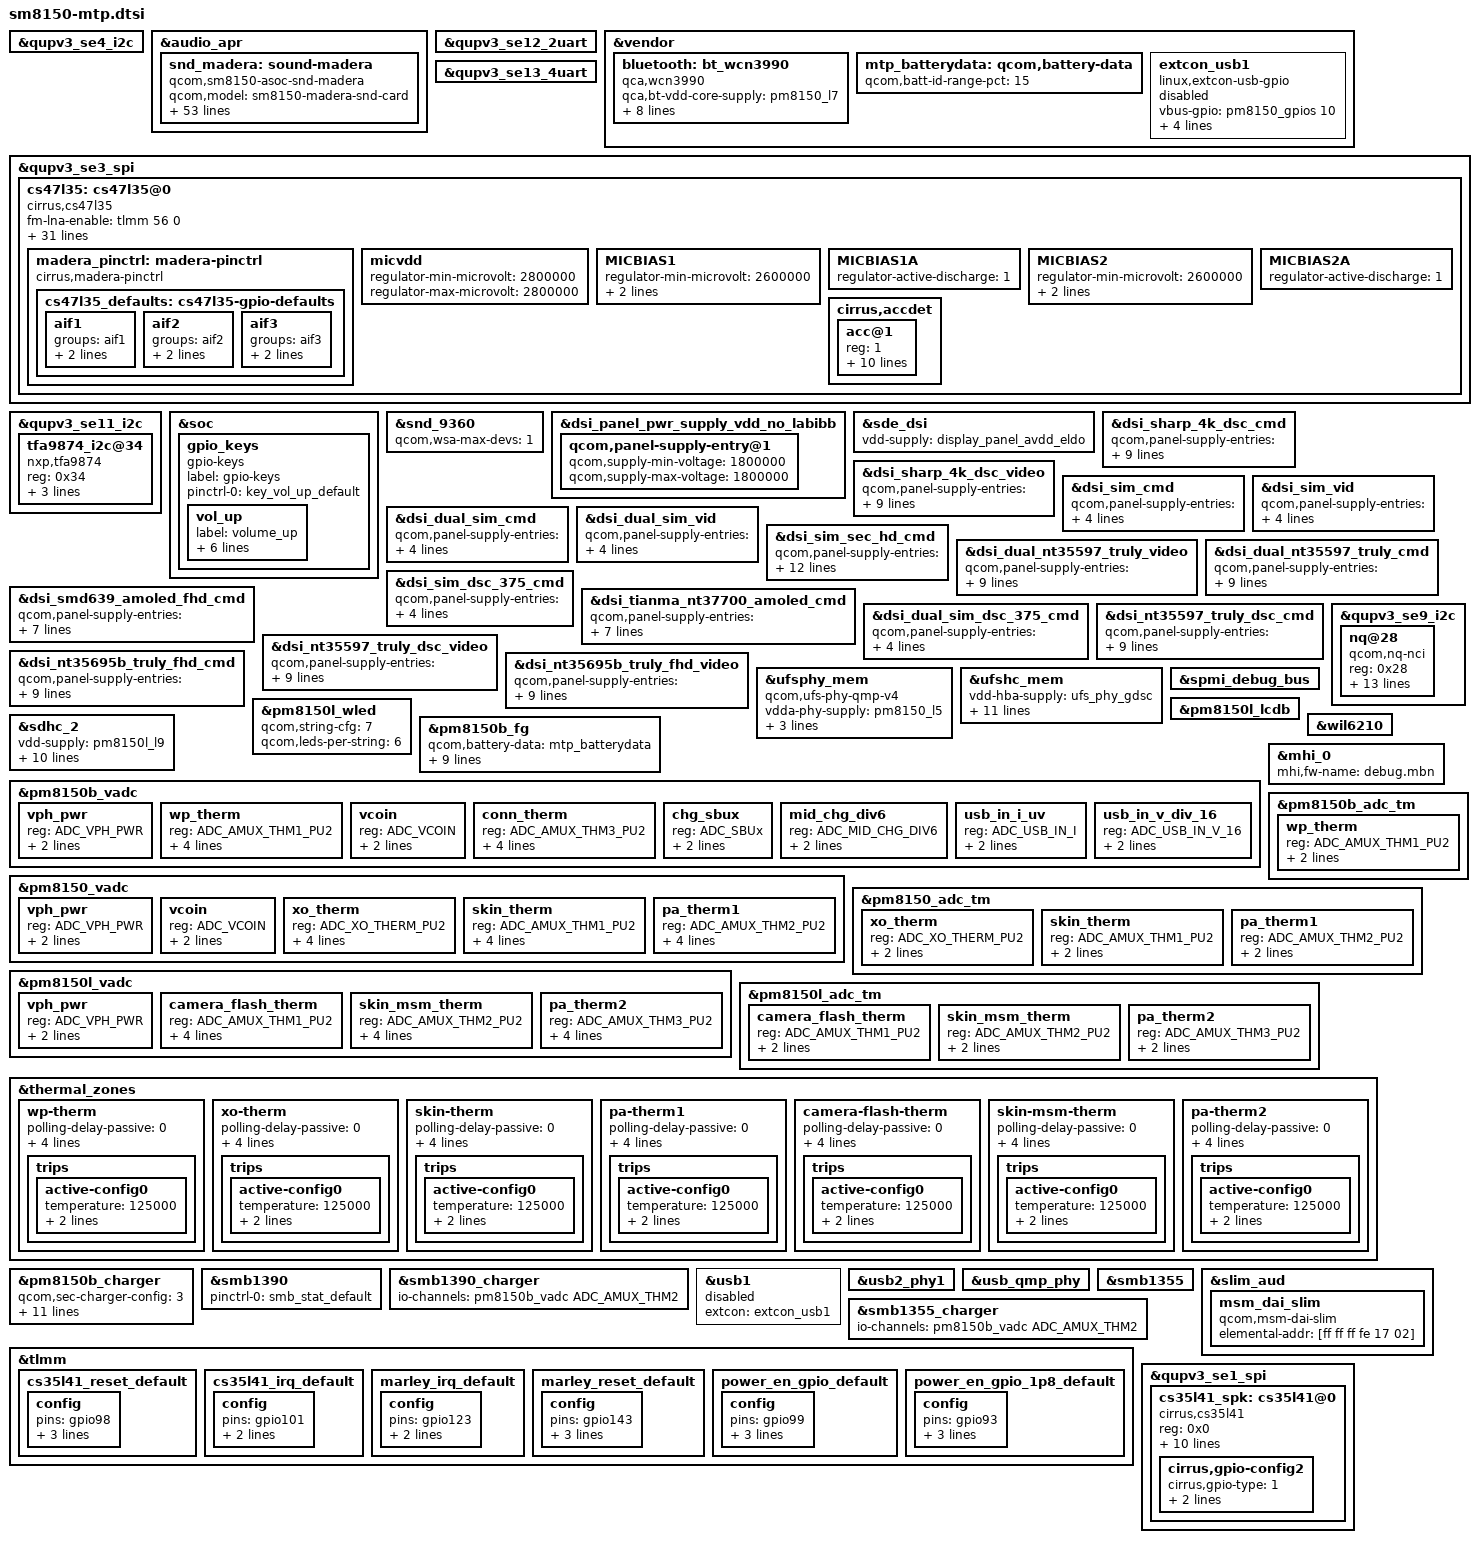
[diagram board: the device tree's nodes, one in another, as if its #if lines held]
/* Copyright (c) 2017-2018, The Linux Foundation. All rights reserved.
 *
 * This program is free software; you can redistribute it and/or modify
 * it under the terms of the GNU General Public License version 2 and
 * only version 2 as published by the Free Software Foundation.
 *
 * This program is distributed in the hope that it will be useful,
 * but WITHOUT ANY WARRANTY; without even the implied warranty of
 * MERCHANTABILITY or FITNESS FOR A PARTICULAR PURPOSE.  See the
 * GNU General Public License for more details.
 */

#include <dt-bindings/gpio/gpio.h>
#include <dt-bindings/input/input.h>
#include <generated/autoconf.h>

#include "sm8150-pmic-overlay.dtsi"
#include "sm8150-sde-display.dtsi"
#ifdef CONFIG_PRODUCT_HEART
#include "sm8150-camera-sensor-heart.dtsi"
#elif defined(CONFIG_PRODUCT_ZIPPO)
#include "sm8150-camera-sensor-zippo.dtsi"
#else
#include "sm8150-camera-sensor-mtp.dtsi"
#endif
#include "sm8150-thermal-overlay.dtsi"

&qupv3_se4_i2c {
#include "smb1390.dtsi"
#include "smb1355.dtsi"
};
#ifdef CONFIG_PRODUCT_HEART
&audio_apr {
	snd_madera: sound-madera {
		compatible = "qcom,sm8150-asoc-snd-madera";
		qcom,model = "sm8150-madera-snd-card";

		asoc-platform = <&pcm0>, <&pcm1>, <&pcm2>, <&voip>, <&voice>,
				<&loopback>, <&compress>, <&hostless>,
				<&afe>, <&lsm>, <&routing>, <&compr>,
				<&pcm_noirq>, <&cs47l35>;
		asoc-platform-names = "msm-pcm-dsp.0", "msm-pcm-dsp.1",
				"msm-pcm-dsp.2", "msm-voip-dsp",
				"msm-pcm-voice", "msm-pcm-loopback",
				"msm-compress-dsp", "msm-pcm-hostless",
				"msm-pcm-afe", "msm-lsm-client",
				"msm-pcm-routing", "msm-compr-dsp",
				"msm-pcm-dsp-noirq","cs47l35-codec";
		asoc-cpu = <&dai_hdmi>, <&dai_dp>,
				<&dai_mi2s0>, <&dai_mi2s1>,
				<&dai_mi2s2>, <&dai_mi2s3>,
				<&dai_mi2s4>, <&dai_pri_auxpcm>,
				<&dai_sec_auxpcm>, <&dai_tert_auxpcm>,
				<&dai_quat_auxpcm>, <&dai_quin_auxpcm>,
				<&sb_0_rx>, <&sb_0_tx>, <&sb_1_rx>, <&sb_1_tx>,
				<&sb_2_rx>, <&sb_2_tx>, <&sb_3_rx>, <&sb_3_tx>,
				<&sb_4_rx>, <&sb_4_tx>, <&sb_5_tx>,
				<&afe_pcm_rx>, <&afe_pcm_tx>, <&afe_proxy_rx>,
				<&afe_proxy_tx>, <&incall_record_rx>,
				<&incall_record_tx>, <&incall_music_rx>,
				<&incall_music_2_rx>, <&sb_5_rx>, <&sb_6_rx>,
				<&sb_7_rx>, <&sb_7_tx>, <&sb_8_tx>,
				<&usb_audio_rx>, <&usb_audio_tx>,
				<&dai_pri_tdm_rx_0>, <&dai_pri_tdm_tx_0>,
				<&dai_sec_tdm_rx_0>, <&dai_sec_tdm_tx_0>,
				<&dai_tert_tdm_rx_0>, <&dai_tert_tdm_tx_0>,
				<&dai_quat_tdm_rx_0>, <&dai_quat_tdm_tx_0>,
				<&dai_quin_tdm_rx_0>, <&dai_quin_tdm_tx_0>;
		asoc-cpu-names = "msm-dai-q6-hdmi.8",  "msm-dai-q6-dp.24608",
				"msm-dai-q6-mi2s.0", "msm-dai-q6-mi2s.1",
				"msm-dai-q6-mi2s.2", "msm-dai-q6-mi2s.3",
				"msm-dai-q6-mi2s.4", "msm-dai-q6-auxpcm.1",
				"msm-dai-q6-auxpcm.2", "msm-dai-q6-auxpcm.3",
				"msm-dai-q6-auxpcm.4", "msm-dai-q6-auxpcm.5",
				"msm-dai-q6-dev.16384", "msm-dai-q6-dev.16385",
				"msm-dai-q6-dev.16386", "msm-dai-q6-dev.16387",
				"msm-dai-q6-dev.16388", "msm-dai-q6-dev.16389",
				"msm-dai-q6-dev.16390", "msm-dai-q6-dev.16391",
				"msm-dai-q6-dev.16392", "msm-dai-q6-dev.16393",
				"msm-dai-q6-dev.16395", "msm-dai-q6-dev.224",
				"msm-dai-q6-dev.225", "msm-dai-q6-dev.241",
				"msm-dai-q6-dev.240", "msm-dai-q6-dev.32771",
				"msm-dai-q6-dev.32772", "msm-dai-q6-dev.32773",
				"msm-dai-q6-dev.32770", "msm-dai-q6-dev.16394",
				"msm-dai-q6-dev.16396", "msm-dai-q6-dev.16398",
				"msm-dai-q6-dev.16399", "msm-dai-q6-dev.16401",
				"msm-dai-q6-dev.28672", "msm-dai-q6-dev.28673",
				"msm-dai-q6-tdm.36864", "msm-dai-q6-tdm.36865",
				"msm-dai-q6-tdm.36880", "msm-dai-q6-tdm.36881",
				"msm-dai-q6-tdm.36896", "msm-dai-q6-tdm.36897",
				"msm-dai-q6-tdm.36912", "msm-dai-q6-tdm.36913",
				"msm-dai-q6-tdm.36928", "msm-dai-q6-tdm.36929";
		fsa4480-i2c-handle = <&fsa4480>;
	};
};
#endif
&qupv3_se12_2uart {
	status = "ok";
};

&vendor {
	bluetooth: bt_wcn3990 {
		compatible = "qca,wcn3990";
		qca,bt-vdd-core-supply = <&pm8150_l7>;
		qca,bt-vdd-pa-supply = <&pm8150l_l2>;
		qca,bt-vdd-ldo-supply = <&pm8150l_l11>;

		qca,bt-vdd-core-voltage-level = <1800000 1800000>;
		qca,bt-vdd-pa-voltage-level = <1304000 1304000>;
		qca,bt-vdd-ldo-voltage-level = <3312000 3312000>;

		qca,bt-vdd-core-current-level = <0>; /* LPM/PFM */
		qca,bt-vdd-pa-current-level = <0>; /* LPM/PFM */
		qca,bt-vdd-ldo-current-level = <0>; /* LPM/PFM */
	};

	mtp_batterydata: qcom,battery-data {
		qcom,batt-id-range-pct = <15>;
		#include "Lenovo_heart_batterydate_Aug28th2018_scud_3300mAh_averaged_MasterSlave.dtsi"
		#include "Lenovo_Zippo_ATL_4000mAh_averaged_MasterSlave_Jan4rd2019_PM8150BGUI10013.dtsi"
	};

	extcon_usb1: extcon_usb1 {
#if defined(CONFIG_PRODUCT_HEART)||defined(CONFIG_PRODUCT_ZIPPO)
		status = "disabled";
#endif
		compatible = "linux,extcon-usb-gpio";
		vbus-gpio = <&pm8150_gpios 10 GPIO_ACTIVE_HIGH>;
		id-gpio = <&tlmm 101 GPIO_ACTIVE_HIGH>;
		vbus-out-gpio = <&pm8150_gpios 9 GPIO_ACTIVE_HIGH>;

		pinctrl-names = "default";
		pinctrl-0 = <&usb2_vbus_det_default
			     &usb2_id_det_default
			     &usb2_vbus_boost_default>;
	};
};

&qupv3_se13_4uart {
	status = "ok";
};

&qupv3_se3_spi {
	status = "ok";
};

&qupv3_se4_i2c {
	status = "ok";
};

#ifdef CONFIG_PRODUCT_ZIPPO
&qupv3_se11_i2c {
	status = "ok";
	tfa9874_i2c@34 {
		compatible = "nxp,tfa9874";
		reg = <0x34>;
		status = "ok";
		reset-gpio = <&tlmm 98 0x0>;
		irq-gpio = <&tlmm 101 0x2008>;
		tfa9874-supply = <&pm8150l_l8>;
	};
};
#endif

&soc {
	gpio_keys {
		compatible = "gpio-keys";
		label = "gpio-keys";

		pinctrl-names = "default";
		pinctrl-0 = <&key_vol_up_default>;

		vol_up {
			label = "volume_up";
			gpios = <&pm8150_gpios 6 GPIO_ACTIVE_LOW>;
			linux,input-type = <1>;
			linux,code = <KEY_VOLUMEUP>;
			gpio-key,wakeup;
			debounce-interval = <15>;
			linux,can-disable;
		};
	};

/*
	qcom,qbt1000 {
		compatible = "qcom,qbt1000";
		clock-names = "core", "iface";
		clock-frequency = <25000000>;
		qcom,ipc-gpio = <&tlmm 118 0>;
		pinctrl-names = "default";
		pinctrl-0 = <&key_home_default>;
		qcom,finger-detect-gpio = <&pm8150_gpios 1 0>;
	};
*/
};

&snd_9360 {
	qcom,wsa-max-devs = <1>;
};

&dsi_panel_pwr_supply_vdd_no_labibb {
	qcom,panel-supply-entry@1 {
		qcom,supply-min-voltage = <1800000>;
		qcom,supply-max-voltage = <1800000>;
	};
};

&sde_dsi {
	vdd-supply = <&display_panel_avdd_eldo>;
};

&dsi_sharp_4k_dsc_cmd {
	qcom,panel-supply-entries = <&dsi_panel_pwr_supply>;
	qcom,mdss-dsi-bl-pmic-control-type = "bl_ctrl_wled";
	qcom,mdss-dsi-bl-min-level = <1>;
	qcom,mdss-dsi-bl-max-level = <4095>;
	qcom,mdss-dsi-mode-sel-gpio-state = "dual_port";
	qcom,panel-mode-gpio = <&tlmm 7 0>;
	qcom,platform-te-gpio = <&tlmm 8 0>;
	qcom,platform-reset-gpio = <&tlmm 6 0>;
};

&dsi_sharp_4k_dsc_video {
	qcom,panel-supply-entries = <&dsi_panel_pwr_supply>;
	qcom,mdss-dsi-bl-pmic-control-type = "bl_ctrl_wled";
	qcom,mdss-dsi-bl-min-level = <1>;
	qcom,mdss-dsi-bl-max-level = <4095>;
	qcom,mdss-dsi-mode-sel-gpio-state = "dual_port";
	qcom,panel-mode-gpio = <&tlmm 7 0>;
	qcom,platform-te-gpio = <&tlmm 8 0>;
	qcom,platform-reset-gpio = <&tlmm 6 0>;
};

&dsi_sim_cmd {
	qcom,panel-supply-entries = <&dsi_panel_pwr_supply>;
	qcom,mdss-dsi-bl-pmic-control-type = "bl_ctrl_dcs";
	qcom,platform-reset-gpio = <&tlmm 6 0>;
};

&dsi_sim_vid {
	qcom,panel-supply-entries = <&dsi_panel_pwr_supply>;
	qcom,mdss-dsi-bl-pmic-control-type = "bl_ctrl_dcs";
	qcom,platform-reset-gpio = <&tlmm 6 0>;
};

&dsi_dual_sim_cmd {
	qcom,panel-supply-entries = <&dsi_panel_pwr_supply>;
	qcom,mdss-dsi-bl-pmic-control-type = "bl_ctrl_dcs";
	qcom,platform-reset-gpio = <&tlmm 6 0>;
};

&dsi_dual_sim_vid {
	qcom,panel-supply-entries = <&dsi_panel_pwr_supply>;
	qcom,mdss-dsi-bl-pmic-control-type = "bl_ctrl_dcs";
	qcom,platform-reset-gpio = <&tlmm 6 0>;
};

&dsi_sim_sec_hd_cmd {
	qcom,panel-supply-entries = <&dsi_panel_pwr_supply>;
	qcom,panel-sec-supply-entries = <&dsi_panel_pwr_supply_vdd_no_labibb>;
	qcom,mdss-dsi-bl-pmic-control-type = "bl_ctrl_wled";
	qcom,mdss-dsi-bl-min-level = <1>;
	qcom,mdss-dsi-bl-max-level = <4095>;
	qcom,mdss-dsi-mode-sel-gpio-state = "single_port";
	qcom,panel-mode-gpio = <&tlmm 7 0>;
	qcom,platform-reset-gpio = <&tlmm 6 0>;
	qcom,panel-sec-mode-gpio = <&tlmm 77 0>;
	qcom,platform-sec-reset-gpio = <&tlmm 66 0>;
};

&dsi_dual_nt35597_truly_video {
	qcom,panel-supply-entries = <&dsi_panel_pwr_supply>;
	qcom,mdss-dsi-bl-pmic-control-type = "bl_ctrl_wled";
	qcom,mdss-dsi-bl-min-level = <1>;
	qcom,mdss-dsi-bl-max-level = <4095>;
	qcom,mdss-dsi-mode-sel-gpio-state = "dual_port";
	qcom,panel-mode-gpio = <&tlmm 7 0>;
	qcom,platform-te-gpio = <&tlmm 8 0>;
	qcom,platform-reset-gpio = <&tlmm 6 0>;
};

&dsi_dual_nt35597_truly_cmd {
	qcom,panel-supply-entries = <&dsi_panel_pwr_supply>;
	qcom,mdss-dsi-bl-pmic-control-type = "bl_ctrl_wled";
	qcom,mdss-dsi-bl-min-level = <1>;
	qcom,mdss-dsi-bl-max-level = <4095>;
	qcom,mdss-dsi-mode-sel-gpio-state = "dual_port";
	qcom,panel-mode-gpio = <&tlmm 7 0>;
	qcom,platform-te-gpio = <&tlmm 8 0>;
	qcom,platform-reset-gpio = <&tlmm 6 0>;
};

&dsi_sim_dsc_375_cmd {
	qcom,panel-supply-entries = <&dsi_panel_pwr_supply>;
	qcom,mdss-dsi-bl-pmic-control-type = "bl_ctrl_dcs";
	qcom,platform-reset-gpio = <&tlmm 6 0>;
};

&dsi_smd639_amoled_fhd_cmd {
	qcom,panel-supply-entries = <&dsi_panel_pwr_supply_vdd_no_labibb>;
	qcom,mdss-dsi-bl-pmic-control-type = "bl_ctrl_dcs";
	qcom,mdss-dsi-mode-sel-gpio-state = "single_port";
	qcom,panel-mode-gpio = <&tlmm 7 0>;
	qcom,platform-te-gpio = <&tlmm 8 0>;
	qcom,platform-reset-gpio = <&tlmm 6 0>;
};

&dsi_tianma_nt37700_amoled_cmd {
	qcom,panel-supply-entries = <&dsi_panel_pwr_supply_vdd_no_labibb>;
	qcom,mdss-dsi-bl-pmic-control-type = "bl_ctrl_dcs";
	qcom,mdss-dsi-mode-sel-gpio-state = "single_port";
	qcom,panel-mode-gpio = <&tlmm 7 0>;
	qcom,platform-te-gpio = <&tlmm 8 0>;
	qcom,platform-reset-gpio = <&tlmm 6 0>;
};

&dsi_dual_sim_dsc_375_cmd {
	qcom,panel-supply-entries = <&dsi_panel_pwr_supply>;
	qcom,mdss-dsi-bl-pmic-control-type = "bl_ctrl_dcs";
	qcom,platform-reset-gpio = <&tlmm 6 0>;
};

&dsi_nt35597_truly_dsc_cmd {
	qcom,panel-supply-entries = <&dsi_panel_pwr_supply>;
	qcom,mdss-dsi-bl-pmic-control-type = "bl_ctrl_wled";
	qcom,mdss-dsi-bl-min-level = <1>;
	qcom,mdss-dsi-bl-max-level = <4095>;
	qcom,mdss-dsi-mode-sel-gpio-state = "single_port";
	qcom,panel-mode-gpio = <&tlmm 7 0>;
	qcom,platform-te-gpio = <&tlmm 8 0>;
	qcom,platform-reset-gpio = <&tlmm 6 0>;
};

&dsi_nt35597_truly_dsc_video {
	qcom,panel-supply-entries = <&dsi_panel_pwr_supply>;
	qcom,mdss-dsi-bl-pmic-control-type = "bl_ctrl_wled";
	qcom,mdss-dsi-bl-min-level = <1>;
	qcom,mdss-dsi-bl-max-level = <4095>;
	qcom,mdss-dsi-mode-sel-gpio-state = "single_port";
	qcom,panel-mode-gpio = <&tlmm 7 0>;
	qcom,platform-te-gpio = <&tlmm 8 0>;
	qcom,platform-reset-gpio = <&tlmm 6 0>;
};

&dsi_nt35695b_truly_fhd_cmd {
	qcom,panel-supply-entries = <&dsi_panel_pwr_supply>;
	qcom,mdss-dsi-bl-pmic-control-type = "bl_ctrl_wled";
	qcom,mdss-dsi-bl-min-level = <1>;
	qcom,mdss-dsi-bl-max-level = <4095>;
	qcom,mdss-dsi-mode-sel-gpio-state = "single_port";
	qcom,panel-mode-gpio = <&tlmm 7 0>;
	qcom,platform-te-gpio = <&tlmm 8 0>;
	qcom,platform-reset-gpio = <&tlmm 6 0>;
};

&dsi_nt35695b_truly_fhd_video {
	qcom,panel-supply-entries = <&dsi_panel_pwr_supply>;
	qcom,mdss-dsi-bl-pmic-control-type = "bl_ctrl_wled";
	qcom,mdss-dsi-bl-min-level = <1>;
	qcom,mdss-dsi-bl-max-level = <4095>;
	qcom,mdss-dsi-mode-sel-gpio-state = "single_port";
	qcom,panel-mode-gpio = <&tlmm 7 0>;
	qcom,platform-te-gpio = <&tlmm 8 0>;
	qcom,platform-reset-gpio = <&tlmm 6 0>;
};

&qupv3_se9_i2c {
	status = "ok";
	nq@28 {
		compatible = "qcom,nq-nci";
		reg = <0x28>;
		qcom,nq-irq = <&tlmm 47 0x00>;
		qcom,nq-ven = <&tlmm 41 0x00>;
		qcom,nq-firm = <&tlmm 48 0x00>;
		qcom,nq-clkreq = <&tlmm 113 0x00>;
		qcom,nq-esepwr = <&tlmm 49 0x00>;
		interrupt-parent = <&tlmm>;
		interrupts = <47 0>;
		interrupt-names = "nfc_irq";
		pinctrl-names = "nfc_active", "nfc_suspend";
		pinctrl-0 = <&nfc_int_active &nfc_enable_active
					&nfc_clk_req_active>;
		pinctrl-1 = <&nfc_int_suspend &nfc_enable_suspend
					&nfc_clk_req_suspend>;
		qcom,clk-src = "BBCLK3";
		clocks = <&clock_rpmh RPMH_LN_BB_CLK3>;
		clock-names = "ref_clk";
		status = "ok";
	};
};

&ufsphy_mem {
	compatible = "qcom,ufs-phy-qmp-v4";

	vdda-phy-supply = <&pm8150_l5>;
	vdda-pll-supply = <&pm8150l_l3>;
	vdda-phy-max-microamp = <90200>;
	vdda-pll-max-microamp = <19000>;

	status = "ok";
};

&ufshc_mem {
	vdd-hba-supply = <&ufs_phy_gdsc>;
	vdd-hba-fixed-regulator;
	vcc-supply = <&pm8150_l10>;
	vcc-voltage-level = <2504000 2950000>;
	vcc-low-voltage-sup;
	vccq-supply = <&pm8150_l9>;
	vccq2-supply = <&pm8150_s4>;
	vcc-max-microamp = <750000>;
	vccq-max-microamp = <700000>;
	vccq2-max-microamp = <750000>;

	qcom,vddp-ref-clk-supply = <&pm8150_l9>;
	qcom,vddp-ref-clk-max-microamp = <100>;

	status = "ok";
};

&spmi_debug_bus {
	status = "ok";
};

&pm8150l_wled {
	qcom,string-cfg= <7>;
	qcom,leds-per-string = <6>;
	status = "ok";
};

&pm8150l_lcdb {
	status = "ok";
};

&pm8150b_fg {
	qcom,battery-data = <&mtp_batterydata>;
	qcom,hold-soc-while-full;
	qcom,linearize-soc;
	qcom,five-pin-battery;
	/* ESR fast calibration */
	qcom,fg-esr-timer-chg-fast = <0 7>;
	qcom,fg-esr-timer-dischg-fast = <0 7>;
	qcom,fg-esr-timer-chg-slow = <0 96>;
	qcom,fg-esr-timer-dischg-slow = <0 96>;
	qcom,fg-esr-cal-soc-thresh = <26 230>;
	qcom,fg-esr-cal-temp-thresh = <10 40>;
};

&sdhc_2 {
	vdd-supply = <&pm8150l_l9>;
	qcom,vdd-voltage-level = <2950000 2960000>;
	qcom,vdd-current-level = <200 800000>;

	vdd-io-supply = <&pm8150l_l6>;
	qcom,vdd-io-voltage-level = <1808000 2960000>;
	qcom,vdd-io-current-level = <200 22000>;

	pinctrl-names = "active", "sleep";
	pinctrl-0 = <&sdc2_clk_on  &sdc2_cmd_on &sdc2_data_on &storage_cd>;
	pinctrl-1 = <&sdc2_clk_off &sdc2_cmd_off &sdc2_data_off &storage_cd>;

	cd-gpios = <&tlmm 96 GPIO_ACTIVE_HIGH>;
};

&pm8150b_vadc {
	vph_pwr {
		reg = <ADC_VPH_PWR>;
		label = "vph_pwr";
		qcom,pre-scaling = <1 3>;
	};

	wp_therm {
		reg = <ADC_AMUX_THM1_PU2>;
		label = "wp_therm";
		qcom,ratiometric;
		qcom,hw-settle-time = <200>;
		qcom,pre-scaling = <1 1>;
	};

	vcoin {
		reg = <ADC_VCOIN>;
		label = "vcoin";
		qcom,pre-scaling = <1 3>;
	};

	conn_therm {
		reg = <ADC_AMUX_THM3_PU2>;
		label = "conn_therm";
		qcom,ratiometric;
		qcom,hw-settle-time = <200>;
		qcom,pre-scaling = <1 1>;
	};

	chg_sbux {
		reg = <ADC_SBUx>;
		label = "chg_sbux";
		qcom,pre-scaling = <1 3>;
	};

	mid_chg_div6 {
		reg = <ADC_MID_CHG_DIV6>;
		label = "chg_mid";
		qcom,pre-scaling = <1 6>;
	};

	usb_in_i_uv {
		reg = <ADC_USB_IN_I>;
		label = "usb_in_i_uv";
		qcom,pre-scaling = <1 1>;
	};

	usb_in_v_div_16 {
		reg = <ADC_USB_IN_V_16>;
		label = "usb_in_v_div_16";
		qcom,pre-scaling = <1 16>;
	};
};

&pm8150_vadc {
	vph_pwr {
		reg = <ADC_VPH_PWR>;
		label = "vph_pwr";
		qcom,pre-scaling = <1 3>;
	};

	vcoin {
		reg = <ADC_VCOIN>;
		label = "vcoin";
		qcom,pre-scaling = <1 3>;
	};

	xo_therm {
		reg = <ADC_XO_THERM_PU2>;
		label = "xo_therm";
		qcom,ratiometric;
		qcom,hw-settle-time = <200>;
		qcom,pre-scaling = <1 1>;
	};

	skin_therm {
		reg = <ADC_AMUX_THM1_PU2>;
		label = "skin_therm";
		qcom,ratiometric;
		qcom,hw-settle-time = <200>;
		qcom,pre-scaling = <1 1>;
	};

	pa_therm1 {
		reg = <ADC_AMUX_THM2_PU2>;
		label = "pa_therm1";
		qcom,ratiometric;
		qcom,hw-settle-time = <200>;
		qcom,pre-scaling = <1 1>;
	};
};

&pm8150l_vadc {
	vph_pwr {
		reg = <ADC_VPH_PWR>;
		label = "vph_pwr";
		qcom,pre-scaling = <1 3>;
	};

	camera_flash_therm {
		reg = <ADC_AMUX_THM1_PU2>;
		label = "camera_flash_therm";
		qcom,ratiometric;
		qcom,hw-settle-time = <200>;
		qcom,pre-scaling = <1 1>;
	};

	skin_msm_therm {
		reg = <ADC_AMUX_THM2_PU2>;
		label = "skin_msm_therm";
		qcom,ratiometric;
		qcom,hw-settle-time = <200>;
		qcom,pre-scaling = <1 1>;
	};

	pa_therm2 {
		reg = <ADC_AMUX_THM3_PU2>;
		label = "pa_therm2";
		qcom,ratiometric;
		qcom,hw-settle-time = <200>;
		qcom,pre-scaling = <1 1>;
	};
};

&wil6210 {
	status = "ok";
};

&mhi_0 {
	mhi,fw-name = "debug.mbn";
};

&pm8150b_adc_tm {
	wp_therm {
		reg = <ADC_AMUX_THM1_PU2>;
		qcom,ratiometric;
		qcom,hw-settle-time = <200>;
	};
};

&pm8150_adc_tm {
	xo_therm {
		reg = <ADC_XO_THERM_PU2>;
		qcom,ratiometric;
		qcom,hw-settle-time = <200>;
	};

	skin_therm {
		reg = <ADC_AMUX_THM1_PU2>;
		qcom,ratiometric;
		qcom,hw-settle-time = <200>;
	};

	pa_therm1 {
		reg = <ADC_AMUX_THM2_PU2>;
		qcom,ratiometric;
		qcom,hw-settle-time = <200>;
	};
};

&pm8150l_adc_tm {
	camera_flash_therm {
		reg = <ADC_AMUX_THM1_PU2>;
		qcom,ratiometric;
		qcom,hw-settle-time = <200>;
	};

	skin_msm_therm {
		reg = <ADC_AMUX_THM2_PU2>;
		qcom,ratiometric;
		qcom,hw-settle-time = <200>;
	};

	pa_therm2 {
		reg = <ADC_AMUX_THM3_PU2>;
		qcom,ratiometric;
		qcom,hw-settle-time = <200>;
	};
};

&thermal_zones {
	wp-therm {
		polling-delay-passive = <0>;
		polling-delay = <0>;
		thermal-governor = "user_space";
		thermal-sensors = <&pm8150b_adc_tm ADC_AMUX_THM1_PU2>;
		trips {
			active-config0 {
				temperature = <125000>;
				hysteresis = <1000>;
				type = "passive";
			};
		};
	};

	xo-therm {
		polling-delay-passive = <0>;
		polling-delay = <0>;
		thermal-governor = "user_space";
		thermal-sensors = <&pm8150_adc_tm ADC_XO_THERM_PU2>;
		trips {
			active-config0 {
				temperature = <125000>;
				hysteresis = <1000>;
				type = "passive";
			};
		};
	};

	skin-therm {
		polling-delay-passive = <0>;
		polling-delay = <0>;
		thermal-governor = "user_space";
		thermal-sensors = <&pm8150_adc_tm ADC_AMUX_THM1_PU2>;
		trips {
			active-config0 {
				temperature = <125000>;
				hysteresis = <1000>;
				type = "passive";
			};
		};
	};

	pa-therm1 {
		polling-delay-passive = <0>;
		polling-delay = <0>;
		thermal-governor = "user_space";
		thermal-sensors = <&pm8150_adc_tm ADC_AMUX_THM2_PU2>;
		trips {
			active-config0 {
				temperature = <125000>;
				hysteresis = <1000>;
				type = "passive";
			};
		};
	};

	camera-flash-therm {
		polling-delay-passive = <0>;
		polling-delay = <0>;
		thermal-governor = "user_space";
		thermal-sensors = <&pm8150l_adc_tm ADC_AMUX_THM1_PU2>;
		trips {
			active-config0 {
				temperature = <125000>;
				hysteresis = <1000>;
				type = "passive";
			};
		};
	};

	skin-msm-therm {
		polling-delay-passive = <0>;
		polling-delay = <0>;
		thermal-governor = "user_space";
		thermal-sensors = <&pm8150l_adc_tm ADC_AMUX_THM2_PU2>;
		trips {
			active-config0 {
				temperature = <125000>;
				hysteresis = <1000>;
				type = "passive";
			};
		};
	};

	pa-therm2 {
		polling-delay-passive = <0>;
		polling-delay = <0>;
		thermal-governor = "user_space";
		thermal-sensors = <&pm8150l_adc_tm ADC_AMUX_THM3_PU2>;
		trips {
			active-config0 {
				temperature = <125000>;
				hysteresis = <1000>;
				type = "passive";
			};
		};
	};
};

&pm8150b_charger {
#ifdef CONFIG_PRODUCT_HEART
	qcom,sec-charger-config = <3>;
#elif defined(CONFIG_PRODUCT_ZIPPO)
	qcom,sec-charger-config = <1>;
#endif
	qcom,auto-recharge-soc = <98>;
	io-channels = <&pm8150b_vadc ADC_MID_CHG_DIV6>,
		      <&pm8150b_vadc ADC_USB_IN_I>,
		      <&pm8150b_vadc ADC_SBUx>,
		      <&pm8150b_vadc ADC_VPH_PWR>,
		      <&pm8150b_vadc ADC_CHG_TEMP>;
	io-channel-names = "mid_voltage",
			   "usb_in_current",
			   "sbux_res",
			   "vph_voltage",
			   "chg_temp";
	qcom,battery-data = <&mtp_batterydata>;
	qcom,step-charging-enable;
	qcom,sw-jeita-enable;
	qcom,wd-bark-time-secs = <16>;
	qcom,suspend-input-on-debug-batt;
};

&smb1390 {
	pinctrl-names = "default";
	pinctrl-0 = <&smb_stat_default>;
	status = "ok";
};

&smb1390_charger {
	io-channels = <&pm8150b_vadc ADC_AMUX_THM2>;
	io-channel-names = "cp_die_temp";
	status = "ok";
};

&usb1 {
	extcon = <&extcon_usb1>;
#if defined(CONFIG_PRODUCT_HEART)||defined(CONFIG_PRODUCT_ZIPPO)
	status = "disabled";
#endif
};

&usb2_phy1 {
	status = "ok";
};

&usb_qmp_phy {
	status = "ok";
};

&smb1355 {
	status = "ok";
};

&smb1355_charger {
	io-channels = <&pm8150b_vadc ADC_AMUX_THM2>;
	io-channel-names = "charger_temp";
	status = "ok";
};
#ifdef CONFIG_PRODUCT_HEART
&slim_aud {
	status = "ok";
	msm_dai_slim {
		compatible = "qcom,msm-dai-slim";
		elemental-addr = [ff ff ff fe 17 02];
	};
};

&tlmm {
     cs35l41_reset_default: cs35l41_reset_default {
             config {
                    pins = "gpio98";
                    output-low;
                    bias-pull-up;
                    drive-strength = <2>;
            };
     };

     cs35l41_irq_default: cs35l41_irq_default {
            config {
                    pins = "gpio101";
                    drive-strength = <2>;
                    bias-pull-up;
           };
     };

    marley_irq_default: marley_irq_default {
        config {
            pins = "gpio123";
            drive-strength = <2>;
            bias-pull-up;
        };
    };

    marley_reset_default: marley_reset_default {
        config {
            pins = "gpio143";
            output-high;
            bias-pull-up;
            drive-strength = <2>;
        };
    };

    power_en_gpio_default: power_en_gpio_default {
		config {
			pins = "gpio99";
			output-low;
			bias-pull-up;
			drive-strength = <2>;
	};
    };
    power_en_gpio_1p8_default:power_en_gpio_1p8_default {
		config {
			pins = "gpio93";
			output-low;
			bias-pull-up;
			drive-strength = <2>;
	};
    };
};

&qupv3_se3_spi {
    status = "okay";
    cs47l35: cs47l35@0 {
        compatible = "cirrus,cs47l35";
        fm-lna-enable = <&tlmm 56 0>;
        spi-max-frequency = <9600000>;
        reg = <0x0>;
        interrupt-parent = <&tlmm>;
	power_en_gpio-gpios = <&tlmm 99 0>;
	power_en_gpio_1p8-gpios = <&tlmm 93 0>;
        interrupts = <123 8>;
        interrupt-controller;
        #interrupt-cells = <2>;
        reset-gpios = <&tlmm 143 0>;
	clock-names = "madera_mclk1";
	clocks = <&clock_rpmh RPMH_LN_BB_CLK2>;
        pinctrl-names = "default","power_en_gpio","enable","disable","power_en_gpio_1p8","active";
        pinctrl-0 = <&marley_irq_default &marley_reset_default>;
	pinctrl-1 = <&power_en_gpio_default>;
	pinctrl-2 = <&madera_rtc_mclk2_enable>;
	pinctrl-3 = <&madera_rtc_mclk2_disable>;
	pinctrl-4 = <&power_en_gpio_1p8_default>;
	pinctrl-5 = <&cs47l35_defaults>;
        AVDD-supply = <&pm8150l_l8>;
        DBVDD1-supply = <&pm8150l_l8>;
        DBVDD2-supply = <&pm8150l_l8>;
        CPVDD-supply = <&pm8150l_l8>;
        CPVDD1-supply = <&pm8150l_l8>;
	DCVDD-supply = <&dummy_vreg>;
        SPKVDD-supply = <&dummy_vreg>;
		fsa4480-mic-supply = <&pm8150l_bob>;
		madera,rgltr-min-voltage = <3700000>;//3008000
		madera,rgltr-max-voltage = <3700000>;
		madera,rgltr-load-current = <2000000>;


	fsa4480-i2c-handle = <&fsa4480>;
        gpio-controller;
        #gpio-cells = <2>;

        cirrus,inmode =   <
			0 0 1 1
			0 0 0 0
	>;
        cirrus,out-mono = <0 0 0 0 0 0>;

	madera_pinctrl: madera-pinctrl {
		compatible = "cirrus,madera-pinctrl";
			cs47l35_defaults: cs47l35-gpio-defaults {
			aif1 {
			groups = "aif1";
			function = "aif1";
			bias-bus-hold;
			};

			aif2 {
			groups = "aif2";
			function = "aif2";
			bias-bus-hold;
			};

			aif3 {
			groups = "aif3";
			function = "aif3";
			bias-bus-hold;
			};
		};
	};

	micvdd {
		regulator-min-microvolt = <2800000>;
		regulator-max-microvolt = <2800000>;
	};

	MICBIAS1 {
		regulator-min-microvolt = <2600000>;
		regulator-max-microvolt = <2600000>;
		cirrus,ext-cap = <1>;
	};
	MICBIAS1A {
		regulator-active-discharge = <1>;
	};

	MICBIAS2 {
		regulator-min-microvolt = <2600000>;
		regulator-max-microvolt = <2600000>;
		cirrus,ext-cap = <1>;
	};
	MICBIAS2A {
		regulator-active-discharge = <1>;
	};

        cirrus,accdet {
            #address-cells = <1>;
            #size-cells = <0>;

            acc@1 {
                reg = <1>;

                cirrus,micd-detect-debounce-ms = <600>;
                cirrus,micd-bias-start-time = <8>;
                cirrus,micd-rate = <6>;
                cirrus,micd-dbtime = <0x1>;
                cirrus,micd-manual-debounce = <2>;
                cirrus,init-mic-delay-ms = <200>;
		cirrus,report-to-input;
                cirrus,micd-ranges = <
                    100 226  /* HEADSETHOOK  */
                    150 582  /* VOICE_ASSIST */
                    295 115  /* VOLUME_UP    */
                    1257 114 /* VOLUME_DOWN  */
                >;
                cirrus,micd-configs = < 1 0 1 0 0
		                        1 0 1 0 0>;
               /* cirrus,gpsw = <1>;*/
            };
       };
    };
};

&qupv3_se1_spi {
	status = "okay";
	cs35l41_spk: cs35l41@0 {
	   compatible = "cirrus,cs35l41";
	   reg = <0x0>;
	   spi-max-frequency = <9600000>;
	   reset-gpios = <&tlmm 98 0>;
	   interrupt-parent = <&tlmm>;
	   interrupts = <101 0>;
	   interrupt-names = "amp_spk_irq";
	   /* cirrus,right-channel-amp; */
	   cirrus,boost-peak-milliamp = <4500>;
	   cirrus,boost-ind-nanohenry = <1000>;
	   cirrus,boost-cap-microfarad = <15>;
	   cirrus,dsp-force-reload;
	   cirrus,asp-sdout-hiz = <0x3>;
	   pinctrl-names = "default";
	   pinctrl-0 = <&cs35l41_reset_default>;
	   cirrus,gpio-config2 {
	   cirrus,gpio-type = <1>; /* 0 indicate gpio, 1 indicate interrupt */
	   cirrus,gpio-src-select = <0x4>;
	   cirrus,gpio-output-enable;
	   };
	};
};
#endif
